AUTOSAR XML (schema 00046)
package /ComponentTypes
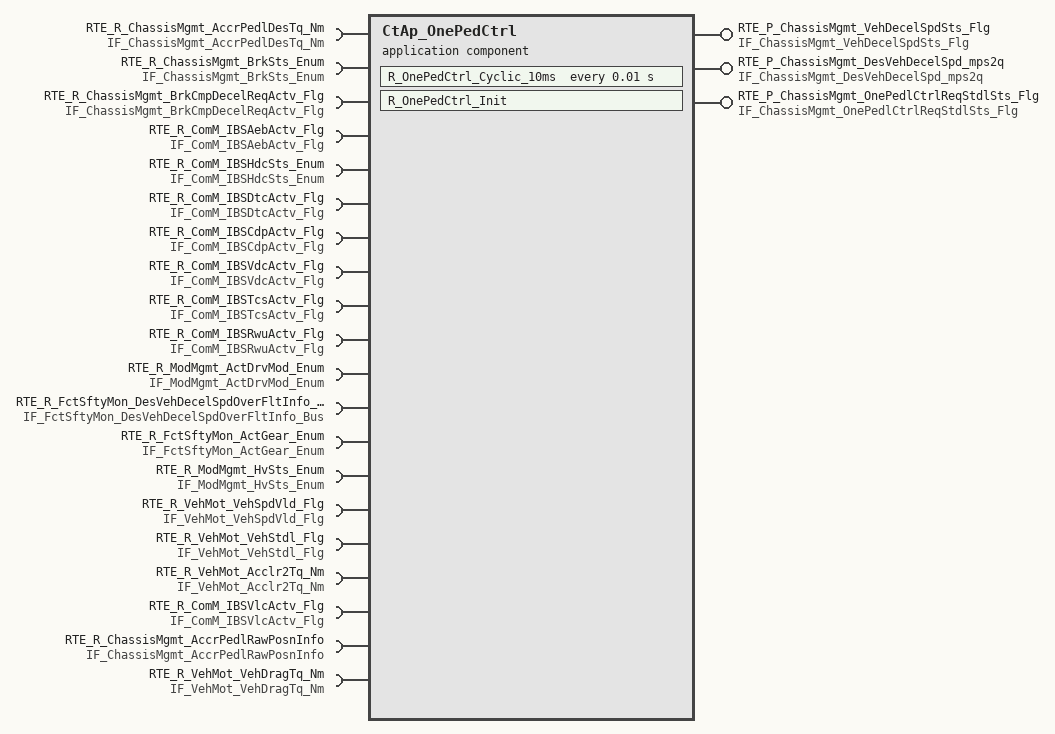
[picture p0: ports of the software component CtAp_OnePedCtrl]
  application sw component type CtAp_OnePedCtrl
    provide port RTE_P_ChassisMgmt_VehDecelSpdSts_Flg: nonqueued-sender-com-spec{data-element=tec_ChassisMgmt_VehDecelSpdSts_Flg, init-value=0}, provided-interface=IF_ChassisMgmt_VehDecelSpdSts_Flg
    provide port RTE_P_ChassisMgmt_DesVehDecelSpd_mps2q: nonqueued-sender-com-spec{data-element=tec_ChassisMgmt_DesVehDecelSpd_mps2q, init-value=0}, provided-interface=IF_ChassisMgmt_DesVehDecelSpd_mps2q
    17 x require port:
      RTE_R_ChassisMgmt_AccrPedlDesTq_Nm: nonqueued-receiver-com-spec{data-element=tec_ChassisMgmt_AccrPedlDesTq_Nm, filter=data-filter-type=ALWAYS, init-value=0}, required-interface=IF_ChassisMgmt_AccrPedlDesTq_Nm
      RTE_R_ChassisMgmt_BrkSts_Enum: nonqueued-receiver-com-spec{data-element=tec_ChassisMgmt_BrkSts_Enum, filter=data-filter-type=ALWAYS, init-value=0}, required-interface=IF_ChassisMgmt_BrkSts_Enum
      RTE_R_ChassisMgmt_BrkCmpDecelReqActv_Flg: nonqueued-receiver-com-spec{data-element=tec_ChassisMgmt_BrkCmpDecelReqActv_Flg, filter=data-filter-type=ALWAYS, init-value=0}, required-interface=IF_ChassisMgmt_BrkCmpDecelReqActv_Flg
      RTE_R_ComM_IBSAebActv_Flg: nonqueued-receiver-com-spec{data-element=tec_ComM_IBSAebActv_Flg, filter=data-filter-type=ALWAYS, init-value=0}, required-interface=IF_ComM_IBSAebActv_Flg
      RTE_R_ComM_IBSHdcSts_Enum: nonqueued-receiver-com-spec{data-element=tec_ComM_IBSHdcSts_Enum, filter=data-filter-type=ALWAYS, init-value=0}, required-interface=IF_ComM_IBSHdcSts_Enum
      RTE_R_ComM_IBSDtcActv_Flg: nonqueued-receiver-com-spec{data-element=tec_ComM_IBSDtcActv_Flg, filter=data-filter-type=ALWAYS, init-value=0}, required-interface=IF_ComM_IBSDtcActv_Flg
      RTE_R_ComM_IBSCdpActv_Flg: nonqueued-receiver-com-spec{data-element=tec_ComM_IBSCdpActv_Flg, filter=data-filter-type=ALWAYS, init-value=0}, required-interface=IF_ComM_IBSCdpActv_Flg
      RTE_R_ComM_IBSVdcActv_Flg: nonqueued-receiver-com-spec{data-element=tec_ComM_IBSVdcActv_Flg, filter=data-filter-type=ALWAYS, init-value=0}, required-interface=IF_ComM_IBSVdcActv_Flg
      RTE_R_ComM_IBSTcsActv_Flg: nonqueued-receiver-com-spec{data-element=tec_ComM_IBSTcsActv_Flg, filter=data-filter-type=ALWAYS, init-value=0}, required-interface=IF_ComM_IBSTcsActv_Flg
      RTE_R_ComM_IBSRwuActv_Flg: nonqueued-receiver-com-spec{data-element=tec_ComM_IBSRwuActv_Flg, filter=data-filter-type=ALWAYS, init-value=0}, required-interface=IF_ComM_IBSRwuActv_Flg
      RTE_R_ModMgmt_ActDrvMod_Enum: nonqueued-receiver-com-spec{data-element=tec_ModMgmt_ActDrvMod_Enum, filter=data-filter-type=ALWAYS, init-value=0}, required-interface=IF_ModMgmt_ActDrvMod_Enum
      RTE_R_FctSftyMon_DesVehDecelSpdOverFltInfo_Bus: nonqueued-receiver-com-spec{data-element=tec_FctSftyMon_DesVehDecelSpdOverFltInfo_Bus, filter=data-filter-type=ALWAYS, init-value=fields=[FctSftyMon_MonStatDesVehDecelSpdOverFltInfo:0, FctSftyMon_MonResDesVehDecelSpdOverFltInfo:0, FctSftyMon_ErrStatDesVehDecelSpdOverFltInfo:0, FctSftyMon_ErrResDesVehDecelSpdOverFltInfo:0]}, required-interface=IF_FctSftyMon_DesVehDecelSpdOverFltInfo_Bus
      RTE_R_FctSftyMon_ActGear_Enum: nonqueued-receiver-com-spec{data-element=tec_FctSftyMon_ActGear_Enum, filter=data-filter-type=ALWAYS, init-value=0}, required-interface=IF_FctSftyMon_ActGear_Enum
      RTE_R_ModMgmt_HvSts_Enum: nonqueued-receiver-com-spec{data-element=tec_ModMgmt_HvSts_Enum, filter=data-filter-type=ALWAYS, init-value=0}, required-interface=IF_ModMgmt_HvSts_Enum
      RTE_R_VehMot_VehSpdVld_Flg: nonqueued-receiver-com-spec{data-element=tec_VehMot_VehSpdVld_Flg, filter=data-filter-type=ALWAYS, init-value=0}, required-interface=IF_VehMot_VehSpdVld_Flg
      RTE_R_VehMot_VehStdl_Flg: nonqueued-receiver-com-spec{data-element=tec_VehMot_VehStdl_Flg, filter=data-filter-type=ALWAYS, init-value=0}, required-interface=IF_VehMot_VehStdl_Flg
      RTE_R_VehMot_Acclr2Tq_Nm: nonqueued-receiver-com-spec{data-element=tec_VehMot_Acclr2Tq_Nm, filter=data-filter-type=ALWAYS, init-value=0}, required-interface=IF_VehMot_Acclr2Tq_Nm
    provide port RTE_P_ChassisMgmt_OnePedlCtrlReqStdlSts_Flg: nonqueued-sender-com-spec{data-element=tec_ChassisMgmt_OnePedlCtrlReqStdlSts_Flg, init-value=0}, provided-interface=IF_ChassisMgmt_OnePedlCtrlReqStdlSts_Flg
    require port RTE_R_ComM_IBSVlcActv_Flg: nonqueued-receiver-com-spec{data-element=tec_ComM_IBSVlcActv_Flg, filter=data-filter-type=ALWAYS, init-value=0}, required-interface=IF_ComM_IBSVlcActv_Flg
    require port RTE_R_ChassisMgmt_AccrPedlRawPosnInfo: nonqueued-receiver-com-spec{data-element=tec_ChassisMgmt_AccrPedlRawPosnInfo, filter=data-filter-type=ALWAYS, init-value=0}, required-interface=IF_ChassisMgmt_AccrPedlRawPosnInfo
    require port RTE_R_VehMot_VehDragTq_Nm: nonqueued-receiver-com-spec{data-element=tec_VehMot_VehDragTq_Nm, filter=data-filter-type=ALWAYS, init-value=0}, required-interface=IF_VehMot_VehDragTq_Nm
    behavior CtAp_OnePedCtrl_InternalBehavior
      timing event TMT_R_OnePedlCtrl_Cyclic_10ms: start-on-event=R_OnePedCtrl_Cyclic_10ms, period=0.01
      init event CtAp_OnePedCtrl_InitEvent: start-on-event=R_OnePedCtrl_Init
      runnable R_OnePedCtrl_Cyclic_10ms
        data-receive-point-by-arguments:
          20 x access:
            REC_RTE_R_ChassisMgmt_AccrPedlDesTq_Nm_tec_ChassisMgmt_AccrPedlDesTq_Nm: accessed-variable=RTE_R_ChassisMgmt_AccrPedlDesTq_Nm.tec_ChassisMgmt_AccrPedlDesTq_Nm
            REC_RTE_R_ChassisMgmt_BrkCmpDecelReqActv_Flg_tec_ChassisMgmt_BrkCmpDecelReqActv_Flg: accessed-variable=RTE_R_ChassisMgmt_BrkCmpDecelReqActv_Flg.tec_ChassisMgmt_BrkCmpDecelReqActv_Flg
            REC_RTE_R_ChassisMgmt_BrkSts_Enum_tec_ChassisMgmt_BrkSts_Enum: accessed-variable=RTE_R_ChassisMgmt_BrkSts_Enum.tec_ChassisMgmt_BrkSts_Enum
            REC_RTE_R_ComM_IBSAebActv_Flg_tec_ComM_IBSAebActv_Flg: accessed-variable=RTE_R_ComM_IBSAebActv_Flg.tec_ComM_IBSAebActv_Flg
            REC_RTE_R_ComM_IBSCdpActv_Flg_tec_ComM_IBSCdpActv_Flg: accessed-variable=RTE_R_ComM_IBSCdpActv_Flg.tec_ComM_IBSCdpActv_Flg
            REC_RTE_R_ComM_IBSDtcActv_Flg_tec_ComM_IBSDtcActv_Flg: accessed-variable=RTE_R_ComM_IBSDtcActv_Flg.tec_ComM_IBSDtcActv_Flg
            REC_RTE_R_ComM_IBSHdcSts_Enum_tec_ComM_IBSHdcSts_Enum: accessed-variable=RTE_R_ComM_IBSHdcSts_Enum.tec_ComM_IBSHdcSts_Enum
            REC_RTE_R_ComM_IBSRwuActv_Flg_tec_ComM_IBSRwuActv_Flg: accessed-variable=RTE_R_ComM_IBSRwuActv_Flg.tec_ComM_IBSRwuActv_Flg
            REC_RTE_R_ComM_IBSTcsActv_Flg_tec_ComM_IBSTcsActv_Flg: accessed-variable=RTE_R_ComM_IBSTcsActv_Flg.tec_ComM_IBSTcsActv_Flg
            REC_RTE_R_ComM_IBSVdcActv_Flg_tec_ComM_IBSVdcActv_Flg: accessed-variable=RTE_R_ComM_IBSVdcActv_Flg.tec_ComM_IBSVdcActv_Flg
            REC_RTE_R_FctSftyMon_ActGear_Enum_tec_FctSftyMon_ActGear_Enum: accessed-variable=RTE_R_FctSftyMon_ActGear_Enum.tec_FctSftyMon_ActGear_Enum
            REC_RTE_R_FctSftyMon_DesVehDecelSpdOverFltInfo_Bus_tec_FctSftyMon_DesVehDecelSpdOverFltInfo_Bus: accessed-variable=RTE_R_FctSftyMon_DesVehDecelSpdOverFltInfo_Bus.tec_FctSftyMon_DesVehDecelSpdOverFltInfo_Bus
            REC_RTE_R_ModMgmt_ActDrvMod_Enum_tec_ModMgmt_ActDrvMod_Enum: accessed-variable=RTE_R_ModMgmt_ActDrvMod_Enum.tec_ModMgmt_ActDrvMod_Enum
            REC_RTE_R_ModMgmt_HvSts_Enum_tec_ModMgmt_HvSts_Enum: accessed-variable=RTE_R_ModMgmt_HvSts_Enum.tec_ModMgmt_HvSts_Enum
            REC_RTE_R_VehMot_VehSpdVld_Flg_tec_VehMot_VehSpdVld_Flg: accessed-variable=RTE_R_VehMot_VehSpdVld_Flg.tec_VehMot_VehSpdVld_Flg
            REC_RTE_R_VehMot_VehStdl_Flg_tec_VehMot_VehStdl_Flg: accessed-variable=RTE_R_VehMot_VehStdl_Flg.tec_VehMot_VehStdl_Flg
            REC_RTE_R_VehMot_Acclr2Tq_Nm_tec_VehMot_Acclr2Tq_Nm: accessed-variable=RTE_R_VehMot_Acclr2Tq_Nm.tec_VehMot_Acclr2Tq_Nm
            REC_RTE_R_ChassisMgmt_AccrPedlRawPosnInfo_tec_ChassisMgmt_AccrPedlRawPosnInfo: accessed-variable=RTE_R_ChassisMgmt_AccrPedlRawPosnInfo.tec_ChassisMgmt_AccrPedlRawPosnInfo
            REC_RTE_R_ComM_IBSVlcActv_Flg_tec_ComM_IBSVlcActv_Flg: accessed-variable=RTE_R_ComM_IBSVlcActv_Flg.tec_ComM_IBSVlcActv_Flg
            REC_RTE_R_VehMot_VehDragTq_Nm_tec_VehMot_VehDragTq_Nm: accessed-variable=RTE_R_VehMot_VehDragTq_Nm.tec_VehMot_VehDragTq_Nm
        data-send-points:
          access SEND_RTE_P_ChassisMgmt_DesVehDecelSpd_mps2q_tec_ChassisMgmt_DesVehDecelSpd_mps2q: accessed-variable=RTE_P_ChassisMgmt_DesVehDecelSpd_mps2q.tec_ChassisMgmt_DesVehDecelSpd_mps2q
          access SEND_RTE_P_ChassisMgmt_VehDecelSpdSts_Flg_tec_ChassisMgmt_VehDecelSpdSts_Flg: accessed-variable=RTE_P_ChassisMgmt_VehDecelSpdSts_Flg.tec_ChassisMgmt_VehDecelSpdSts_Flg
          access SEND_RTE_P_ChassisMgmt_OnePedlCtrlReqStdlSts_Flg_tec_ChassisMgmt_OnePedlCtrlReqStdlSts_Flg: accessed-variable=RTE_P_ChassisMgmt_OnePedlCtrlReqStdlSts_Flg.tec_ChassisMgmt_OnePedlCtrlReqStdlSts_Flg
      runnable R_OnePedCtrl_Init
  swc implementation CtAp_OnePedCtrl_Implementation: behavior=CtAp_OnePedCtrl_InternalBehavior
